# QOLINK_DEV register map
File version: 0.1
QOLink Initial 1-Byte Transfer Register Map
Registers are 32-bit, read-write, reset 0x0 unless marked. A register's access mark holds for its fields unless they carry their own. Offsets are from the block's base; lines under a group give offsets from that group; [hi:lo] are bit positions; {n}, {i} and the like mark numbered series; 'fields as' and 'values as' point back to an identical list; <NAME> marks a mode.

## Memory map
0xFFF60000 QOLINK size 0x8 — QOLink Point-to-Point Communication Peripheral

## QOLINK — QOLink Point-to-Point Communication Peripheral
Base 0xFFF60000
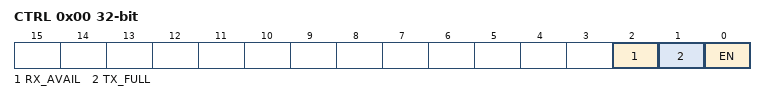
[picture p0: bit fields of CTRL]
0x00 CTRL — Control and Status Register
  [2] RX_AVAIL — Receive Byte Available Flag
  [1] TX_FULL — Transmit Buffer Full Flag
  [0] EN — Enable QOLink Peripheral
0x04 DATA — Transmit and Receive 1-Byte Data Register
  [7:0] BYTE — TX/RX 8-bit Data Field
